VERSION "HIPBNYYYYYYYYYYYYYYYYYYYYYYYYYYYNNNNNNNNNN/4/%%%/4/'%**4NNN///"

NS_ :

BS_:

BU_: Vector__XXX

BO_ 500 ambient: 8 Vector__XXX
 SG_ temperatur : 8|8@1+ (0.078,10.094) [10|30] "°C" Vector__XXX
 SG_ pressure : 0|8@1+ (0.39,963.72) [963|1064] "hPa" Vector__XXX

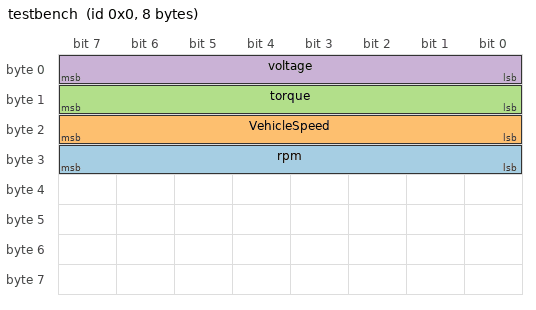
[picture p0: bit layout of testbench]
BO_ 0 testbench: 8 Vector__XXX
 SG_ rpm : 24|8@1+ (100,0) [0|25600] "rpm" Vector__XXX
 SG_ VehicleSpeed : 16|8@1+ (1,0) [0|256] "km/h" Vector__XXX
 SG_ torque : 8|8@1+ (1,-127) [-127|127] "Nm" Vector__XXX
 SG_ voltage : 0|8@1+ (1,0) [0|256] "V" Vector__XXX
